# STM32G563xx register map
File version: 1.0
Registers are 32-bit, read-write, reset 0x0 unless marked. A register's access mark holds for its fields unless they carry their own. Offsets are from the block's base; [hi:lo] are bit positions.

## SPI2 — Serial peripheral interface (SPI)
Base 0x40003800
Same registers: SPI3 0x40003C00, SPI1 0x40013000
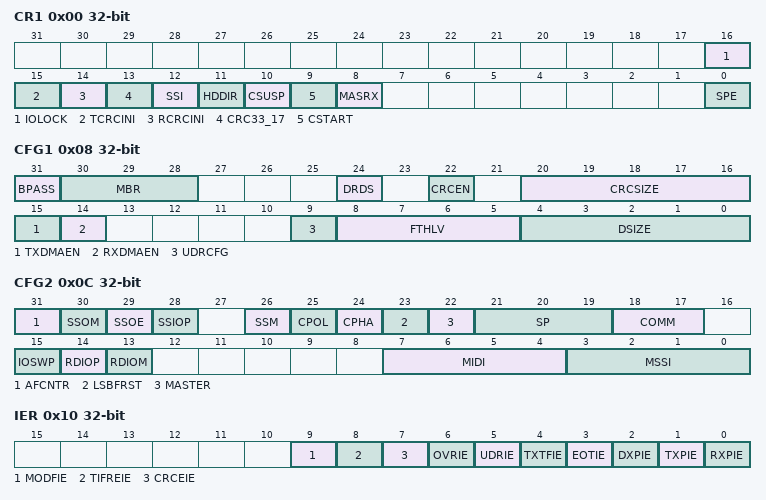
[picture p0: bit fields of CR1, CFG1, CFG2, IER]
0x00 CR1 — SPI/I2S control register 1
  [16] IOLOCK
  [15] TCRCINI
  [14] RCRCINI
  [13] CRC33_17
  [12] SSI — Internal slave select signal input level
  [11] HDDIR — Rx/Tx direction at half-duplex mode
  [10] CSUSP — master suspend request
  [9] CSTART — master transfer start
  [8] MASRX — master automatic suspension in Receive mode
  [0] SPE — serial peripheral enable
0x04 CR2 — SPI/I2S control register 2
  [15:0] TSIZE — number of data at current transfer
0x08 CFG1 — SPI/I2S configuration register 1
  [31] BPASS
  [30:28] MBR — master baud rate prescaler setting
  [24] DRDS — data sampling delay on master input (MISO)
  [22] CRCEN — hardware CRC computation enable
  [20:16] CRCSIZE
  [15] TXDMAEN — Tx DMA stream enable
  [14] RXDMAEN — Rx DMA stream enable
  [9] UDRCFG
  [8:5] FTHLV — FIFO threshold level
  [4:0] DSIZE — number of bits in a single SPI data frame
0x0C CFG2 — SPI/I2S configuration register 2
  [31] AFCNTR — alternate function GPIOs control
  [30] SSOM — NSS output management in master mode
  [29] SSOE — NSS output enable
  [28] SSIOP — NSS input/output polarity
  [26] SSM
  [25] CPOL — clock polarity
  [24] CPHA — clock phase
  [23] LSBFRST — data frame format
  [22] MASTER — SPI master
  [21:19] SP — serial protocol
  [18:17] COMM — SPI Communication Mode
  [15] IOSWP — swap functionality of MISO and MOSI pins
  [14] RDIOP — RDY signal input/output polarity
  [13] RDIOM — RDY signal input/output management
  [7:4] MIDI — Master Inter-Data Idleness
  [3:0] MSSI — Master NSS Idleness
0x10 IER — SPI/I2S interrupt enable register
  [9] MODFIE — mode Fault interrupt enable
  [8] TIFREIE — TIFRE interrupt enable
  [7] CRCEIE — CRC error interrupt enable
  [6] OVRIE — OVR interrupt enable
  [5] UDRIE — UDR interrupt enable
  [4] TXTFIE — TXTF interrupt enable
  [3] EOTIE — EOT, SUSP and TXC interrupt enable
  [2] DXPIE — DXP interrupt enabled
  [1] TXPIE — TXP interrupt enable
  [0] RXPIE — RXP interrupt enable
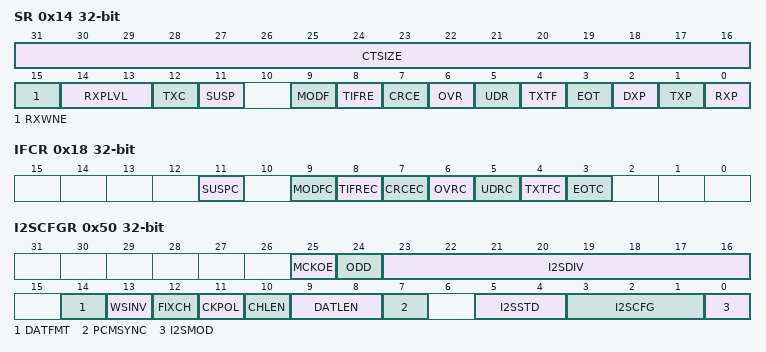
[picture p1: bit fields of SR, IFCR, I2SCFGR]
0x14 SR ro — SPI/I2S status register
  [31:16] CTSIZE
  [15] RXWNE — RxFIFO word not empty
  [14:13] RXPLVL — RxFIFO packing level
  [12] TXC — TxFIFO transmission complete
  [11] SUSP — suspension status
  [9] MODF — mode fault
  [8] TIFRE — TI frame format error
  [7] CRCE — CRC error
  [6] OVR — overrun
  [5] UDR — underrun
  [4] TXTF — transmission transfer filled
  [3] EOT — end of transfer
  [2] DXP — duplex packet
  [1] TXP — Tx-packet space available
  [0] RXP — Rx-packet available
0x18 IFCR — SPI/I2S interrupt/status flags clear register
  [11] SUSPC — Suspend flag clear
  [9] MODFC — mode fault flag clear
  [8] TIFREC — TI frame format error flag clear
  [7] CRCEC — CRC error flag clear
  [6] OVRC — overrun flag clear
  [5] UDRC — underrun flag clear
  [4] TXTFC — transmission transfer filled flag clear
  [3] EOTC — end of transfer flag clear
0x20 TXDR — SPI/I2S transmit data register
  [31:0] TXDR — transmit data register
0x30 RXDR ro — SPI/I2S receive data register
  [31:0] RXDR — receive data register
0x40 CRCPOLY — SPI/I2S polynomial register
  [31:0] CRCPOLY — CRC polynomial register
0x44 TXCRC ro — SPI/I2S transmitter CRC register
  [31:0] TXCRC — CRC register for transmitter
0x48 RXCRC ro — SPI/I2S receiver CRC register
  [31:0] RXCRC — CRC register for receiver
0x4C UDRDR — SPI/I2S underrun data register
  [31:0] UDRDR — data at slave underrun condition
0x50 I2SCFGR — SPI/I2S configuration register
  [25] MCKOE — master clock output enable
  [24] ODD — odd factor for the prescaler
  [23:16] I2SDIV — IS linear prescaler
  [14] DATFMT — data format
  [13] WSINV — word select inversion
  [12] FIXCH — fixed channel length in slave
  [11] CKPOL — serial audio clock polarity
  [10] CHLEN
  [9:8] DATLEN — data length to be transferred
  [7] PCMSYNC — PCM frame synchronization
  [5:4] I2SSTD — IS standard selection
  [3:1] I2SCFG — I2S configuration mode
  [0] I2SMOD — I2S mode selection
